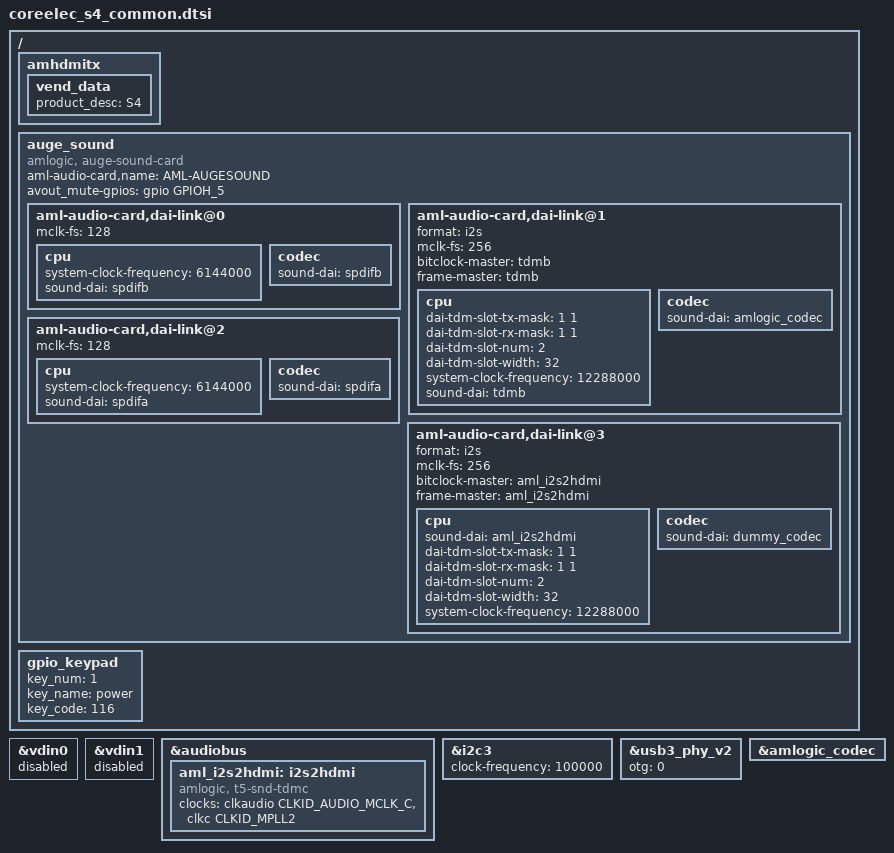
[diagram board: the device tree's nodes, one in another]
#include "coreelec_common.dtsi"

/ {
	amhdmitx: amhdmitx{
		vend_data: vend_data{ /* Should modified by Customer */
			product_desc = "S4"; /* Max Chars: 16 */
		};
	};

	/delete-node/ auge_sound;
	auge_sound {
		compatible = "amlogic, auge-sound-card";
		aml-audio-card,name = "AML-AUGESOUND";

		/*avout mute gpio*/
		avout_mute-gpios = <&gpio GPIOH_5 GPIO_ACTIVE_HIGH>;

		aml-audio-card,dai-link@0 {
			mclk-fs = <128>;
			cpu {
				system-clock-frequency = <6144000>;
				sound-dai = <&spdifb>;
			};
			codec {
				sound-dai = <&spdifb>;
			};
		};

		aml-audio-card,dai-link@1 {
			format = "i2s";
			mclk-fs = <256>;
			bitclock-master = <&tdmb>;
			frame-master = <&tdmb>;
			cpu {
				dai-tdm-slot-tx-mask = <1 1>;
				dai-tdm-slot-rx-mask = <1 1>;
				dai-tdm-slot-num = <2>;
				dai-tdm-slot-width = <32>;
				system-clock-frequency = <12288000>;
				sound-dai = <&tdmb>;
			};
			codec {
				sound-dai = <&amlogic_codec>;
			};
		};

		aml-audio-card,dai-link@2 {
			mclk-fs = <128>;
			cpu {
				system-clock-frequency = <6144000>;
				sound-dai = <&spdifa>;
			};
			codec {
				sound-dai = <&spdifa>;
			};
		};

		aml-audio-card,dai-link@3 {
			format = "i2s";
			mclk-fs = <256>;
			bitclock-master = <&aml_i2s2hdmi>;
			frame-master = <&aml_i2s2hdmi>;
			cpu {
				sound-dai = <&aml_i2s2hdmi>;
				dai-tdm-slot-tx-mask = <1 1>;
				dai-tdm-slot-rx-mask = <1 1>;
				dai-tdm-slot-num = <2>;
				dai-tdm-slot-width = <32>;
				system-clock-frequency = <12288000>;
			};
			codec {
				sound-dai = <&dummy_codec>;
			};
		};
	};

	gpio_keypad {
		key_num = <1>;
		key_name = "power";
		key_code = <116>;
	};
};

&vdin0 {
	status = "disabled";
};

&vdin1 {
	status = "disabled";
};

&audiobus {
	aml_i2s2hdmi: i2s2hdmi {
		compatible = "amlogic, t5-snd-tdmc";
		clocks = <&clkaudio CLKID_AUDIO_MCLK_C
				&clkc CLKID_MPLL2>;
		clock-names = "mclk", "clk_srcpll";
	};
};

&i2c3 {
	clock-frequency = <100000>; /* default 100k */
	/delete-node/ tlc59116@60;
};

&usb3_phy_v2 {
	otg = <0>;
};

&amlogic_codec {
	/delete-property/ tocodec_inout;
	/delete-property/ tdmout_index;
};
